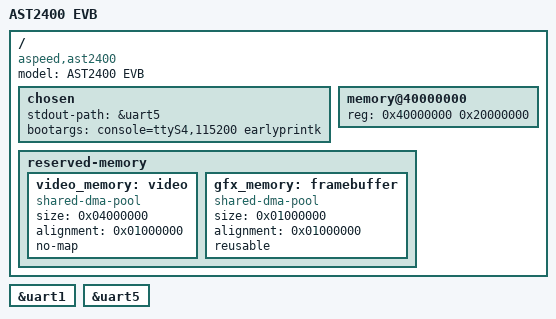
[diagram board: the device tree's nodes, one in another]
// SPDX-License-Identifier: GPL-2.0+
/dts-v1/;

#include "aspeed-g4.dtsi"
#include <dt-bindings/gpio/aspeed-gpio.h>

/ {
	model = "AST2400 EVB";
	compatible = "aspeed,ast2400";

	chosen {
		stdout-path = &uart5;
		bootargs = "console=ttyS4,115200 earlyprintk";
	};

	memory@40000000 {
		reg = <0x40000000 0x20000000>;
	};

	reserved-memory {
		#address-cells = <1>;
		#size-cells = <1>;
		ranges;

		video_memory: video {
			size = <0x04000000>;
			alignment = <0x01000000>;
			compatible = "shared-dma-pool";
			no-map;
		};

		gfx_memory: framebuffer {
			size = <0x01000000>;
			alignment = <0x01000000>;
			compatible = "shared-dma-pool";
			reusable;
		};
	};
};

&uart1 {
	status = "okay";
};

&uart5 {
	status = "okay";
};

#if 0
&gfx {
	status = "okay";
	memory-region = <&gfx_memory>;
};
#endif
